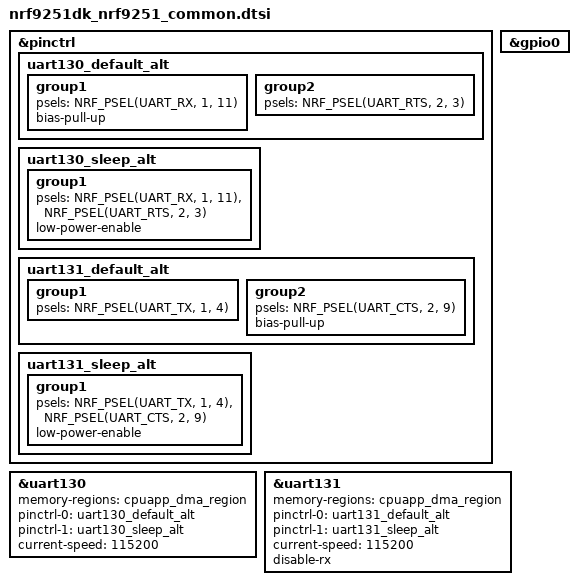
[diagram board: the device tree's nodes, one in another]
/*
 * Copyright (c) 2026 Nordic Semiconductor ASA
 *
 * SPDX-License-Identifier: LicenseRef-Nordic-5-Clause
 */

/* Test requires loopbacks:
 * TX-RX: P1.04 - P1.11
 * RTS-CTS: P2.03 - P2.09
 */

&pinctrl {
	uart130_default_alt: uart130_default_alt {
		group1 {
			psels = <NRF_PSEL(UART_RX, 1, 11)>;
			bias-pull-up;
		};

		group2 {
			psels = <NRF_PSEL(UART_RTS, 2, 3)>;
		};
	};

	uart130_sleep_alt: uart130_sleep_alt {
		group1 {
			psels = <NRF_PSEL(UART_RX, 1, 11)>,
				<NRF_PSEL(UART_RTS, 2, 3)>;
			low-power-enable;
		};
	};
};

&pinctrl {
	uart131_default_alt: uart131_default_alt {
		group1 {
			psels = <NRF_PSEL(UART_TX, 1, 4)>;
		};

		group2 {
			psels = <NRF_PSEL(UART_CTS, 2, 9)>;
			bias-pull-up;
		};
	};

	uart131_sleep_alt: uart131_sleep_alt {
		group1 {
			psels = <NRF_PSEL(UART_TX, 1, 4)>,
				<NRF_PSEL(UART_CTS, 2, 9)>;
			low-power-enable;
		};
	};
};

&gpio0 {
	status = "okay";
};

dut: &uart130 {
	status = "okay";
	memory-regions = <&cpuapp_dma_region>;
	pinctrl-0 = <&uart130_default_alt>;
	pinctrl-1 = <&uart130_sleep_alt>;
	pinctrl-names = "default", "sleep";
	current-speed = <115200>;
};

dut_aux: &uart131 {
	status = "okay";
	memory-regions = <&cpuapp_dma_region>;
	pinctrl-0 = <&uart131_default_alt>;
	pinctrl-1 = <&uart131_sleep_alt>;
	pinctrl-names = "default", "sleep";
	current-speed = <115200>;
	disable-rx;
};
